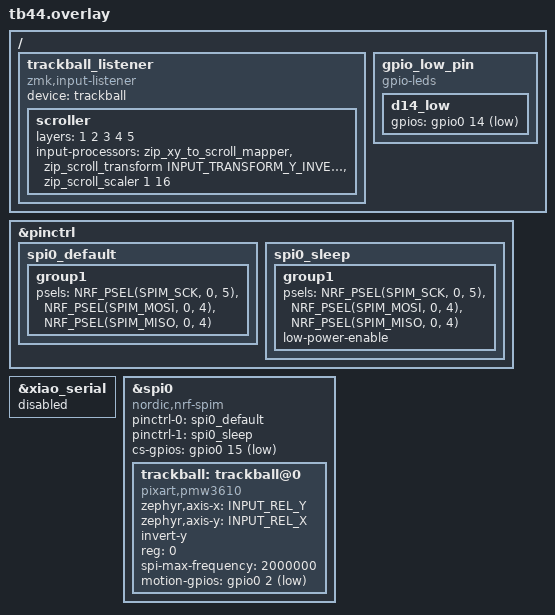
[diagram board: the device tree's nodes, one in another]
#include "tb44.dtsi"
#include <zephyr/dt-bindings/input/input-event-codes.h>
#include <dt-bindings/zmk/input_transform.h>
#include <input/processors.dtsi>

/ {
    trackball_listener {
        compatible = "zmk,input-listener";
        device = <&trackball>;
        scroller {
            layers = <1 2 3 4 5>;
            input-processors = <
                &zip_xy_to_scroll_mapper                       // XY移動でスクロール
                &zip_scroll_transform INPUT_TRANSFORM_Y_INVERT // スクロールのY軸を反転
                &zip_scroll_scaler 1 16                        // スクロール感度調整
            >;
        };
    };
};
/ {
    gpio_low_pin {
        compatible = "gpio-leds";
        d14_low: d14_low {
            gpios = <&gpio0 14 GPIO_ACTIVE_LOW>;
        };
    };
};
&pinctrl {
    spi0_default: spi0_default {
        group1 {
            psels = <NRF_PSEL(SPIM_SCK, 0, 5)>,
                <NRF_PSEL(SPIM_MOSI, 0, 4)>,
                <NRF_PSEL(SPIM_MISO, 0, 4)>;
        };
    };

    spi0_sleep: spi0_sleep {
        group1 {
            psels = <NRF_PSEL(SPIM_SCK, 0, 5)>,
                <NRF_PSEL(SPIM_MOSI, 0, 4)>,
                <NRF_PSEL(SPIM_MISO, 0, 4)>;
            low-power-enable;
        };
    };
};

&xiao_serial { status = "disabled"; };

&spi0 {
    status = "okay";
    compatible = "nordic,nrf-spim";
    pinctrl-0 = <&spi0_default>;
    pinctrl-1 = <&spi0_sleep>;
    pinctrl-names = "default", "sleep";
    cs-gpios = <&gpio0 15 GPIO_ACTIVE_LOW>;
    trackball: trackball@0 {
        status = "okay";
        compatible = "pixart,pmw3610";
        zephyr,axis-x = <INPUT_REL_Y>; 
        zephyr,axis-y = <INPUT_REL_X>;
        invert-y;
        reg = <0>;
        spi-max-frequency = <2000000>;
        motion-gpios = <&gpio0 2 (GPIO_ACTIVE_LOW | GPIO_PULL_UP)>;
    };
};
